# iostr735 register map
Registers are 16-bit, access not given, no defined reset value unless marked. A register's access mark holds for its fields unless they carry their own. Addresses are absolute; registers are grouped by the start of their names; [hi:lo] are bit positions; {n}, {i} and the like mark numbered series.

## TIM1
0xFFFFAC00 TIM1_ICAR
0xFFFFAC04 TIM1_ICBR
0xFFFFAC08 TIM1_OCAR
0xFFFFAC0C TIM1_OCBR
0xFFFFAC10 TIM1_CNTR
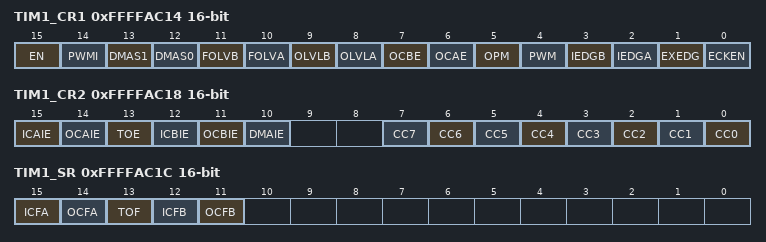
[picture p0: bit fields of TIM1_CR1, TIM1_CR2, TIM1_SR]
0xFFFFAC14 TIM1_CR1
  [15] EN, [14] PWMI, [13] DMAS1, [12] DMAS0, [11] FOLVB, [10] FOLVA, [9] OLVLB, [8] OLVLA, [7] OCBE, [6] OCAE, [5] OPM, [4] PWM, [3] IEDGB, [2] IEDGA, [1] EXEDG, [0] ECKEN
0xFFFFAC18 TIM1_CR2
  [15] ICAIE, [14] OCAIE, [13] TOE, [12] ICBIE, [11] OCBIE, [10] DMAIE, [n] CC{n} (n=0..7)
0xFFFFAC1C TIM1_SR
  [15] ICFA, [14] OCFA, [13] TOF, [12] ICFB, [11] OCFB

## TIM5
0xFFFFB000 TIM5_ICAR
0xFFFFB004 TIM5_ICBR
0xFFFFB008 TIM5_OCAR
0xFFFFB00C TIM5_OCBR
0xFFFFB010 TIM5_CNTR
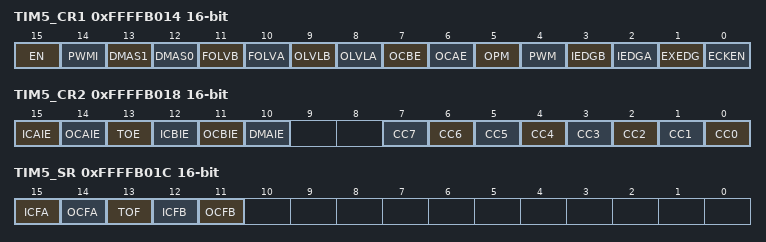
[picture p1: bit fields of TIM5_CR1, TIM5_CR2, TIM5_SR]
0xFFFFB014 TIM5_CR1
  [15] EN, [14] PWMI, [13] DMAS1, [12] DMAS0, [11] FOLVB, [10] FOLVA, [9] OLVLB, [8] OLVLA, [7] OCBE, [6] OCAE, [5] OPM, [4] PWM, [3] IEDGB, [2] IEDGA, [1] EXEDG, [0] ECKEN
0xFFFFB018 TIM5_CR2
  [15] ICAIE, [14] OCAIE, [13] TOE, [12] ICBIE, [11] OCBIE, [10] DMAIE, [n] CC{n} (n=0..7)
0xFFFFB01C TIM5_SR
  [15] ICFA, [14] OCFA, [13] TOF, [12] ICFB, [11] OCFB

## TIM6
0xFFFFB080 TIM6_ICAR
0xFFFFB084 TIM6_ICBR
0xFFFFB088 TIM6_OCAR
0xFFFFB08C TIM6_OCBR
0xFFFFB090 TIM6_CNTR
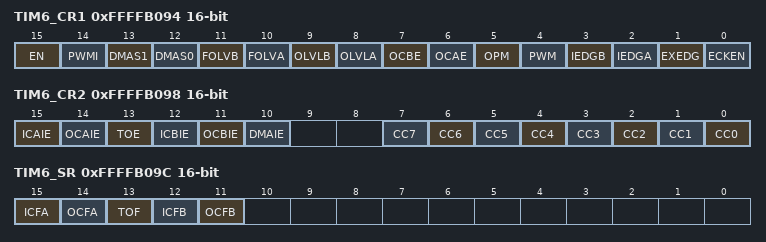
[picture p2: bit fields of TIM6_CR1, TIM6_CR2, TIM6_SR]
0xFFFFB094 TIM6_CR1
  [15] EN, [14] PWMI, [13] DMAS1, [12] DMAS0, [11] FOLVB, [10] FOLVA, [9] OLVLB, [8] OLVLA, [7] OCBE, [6] OCAE, [5] OPM, [4] PWM, [3] IEDGB, [2] IEDGA, [1] EXEDG, [0] ECKEN
0xFFFFB098 TIM6_CR2
  [15] ICAIE, [14] OCAIE, [13] TOE, [12] ICBIE, [11] OCBIE, [10] DMAIE, [n] CC{n} (n=0..7)
0xFFFFB09C TIM6_SR
  [15] ICFA, [14] OCFA, [13] TOF, [12] ICFB, [11] OCFB

## TIM7
0xFFFFB100 TIM7_ICAR
0xFFFFB104 TIM7_ICBR
0xFFFFB108 TIM7_OCAR
0xFFFFB10C TIM7_OCBR
0xFFFFB110 TIM7_CNTR
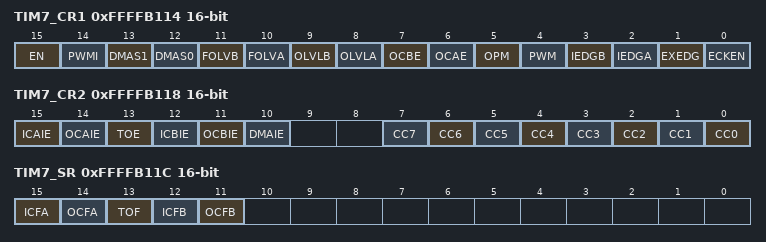
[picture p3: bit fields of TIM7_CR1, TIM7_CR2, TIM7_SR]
0xFFFFB114 TIM7_CR1
  [15] EN, [14] PWMI, [13] DMAS1, [12] DMAS0, [11] FOLVB, [10] FOLVA, [9] OLVLB, [8] OLVLA, [7] OCBE, [6] OCAE, [5] OPM, [4] PWM, [3] IEDGB, [2] IEDGA, [1] EXEDG, [0] ECKEN
0xFFFFB118 TIM7_CR2
  [15] ICAIE, [14] OCAIE, [13] TOE, [12] ICBIE, [11] OCBIE, [10] DMAIE, [n] CC{n} (n=0..7)
0xFFFFB11C TIM7_SR
  [15] ICFA, [14] OCFA, [13] TOF, [12] ICFB, [11] OCFB

## TIM8
0xFFFFB180 TIM8_ICAR
0xFFFFB184 TIM8_ICBR
0xFFFFB188 TIM8_OCAR
0xFFFFB18C TIM8_OCBR
0xFFFFB190 TIM8_CNTR
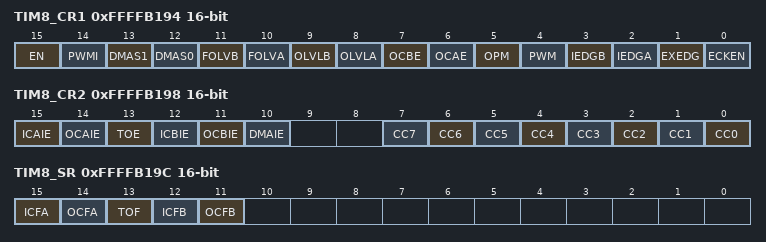
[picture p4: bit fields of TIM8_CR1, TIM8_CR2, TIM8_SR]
0xFFFFB194 TIM8_CR1
  [15] EN, [14] PWMI, [13] DMAS1, [12] DMAS0, [11] FOLVB, [10] FOLVA, [9] OLVLB, [8] OLVLA, [7] OCBE, [6] OCAE, [5] OPM, [4] PWM, [3] IEDGB, [2] IEDGA, [1] EXEDG, [0] ECKEN
0xFFFFB198 TIM8_CR2
  [15] ICAIE, [14] OCAIE, [13] TOE, [12] ICBIE, [11] OCBIE, [10] DMAIE, [n] CC{n} (n=0..7)
0xFFFFB19C TIM8_SR
  [15] ICFA, [14] OCFA, [13] TOF, [12] ICFB, [11] OCFB

## TIM9
0xFFFFB200 TIM9_ICAR
0xFFFFB204 TIM9_ICBR
0xFFFFB208 TIM9_OCAR
0xFFFFB20C TIM9_OCBR
0xFFFFB210 TIM9_CNTR
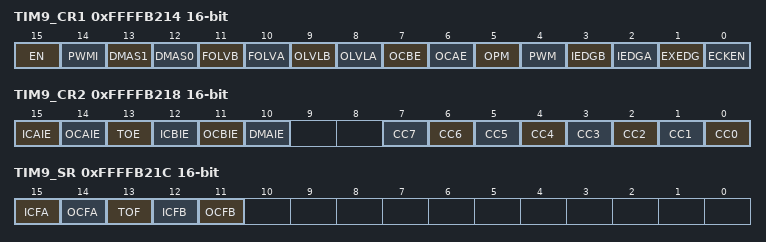
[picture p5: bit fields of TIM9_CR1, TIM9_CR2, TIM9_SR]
0xFFFFB214 TIM9_CR1
  [15] EN, [14] PWMI, [13] DMAS1, [12] DMAS0, [11] FOLVB, [10] FOLVA, [9] OLVLB, [8] OLVLA, [7] OCBE, [6] OCAE, [5] OPM, [4] PWM, [3] IEDGB, [2] IEDGA, [1] EXEDG, [0] ECKEN
0xFFFFB218 TIM9_CR2
  [15] ICAIE, [14] OCAIE, [13] TOE, [12] ICBIE, [11] OCBIE, [10] DMAIE, [n] CC{n} (n=0..7)
0xFFFFB21C TIM9_SR
  [15] ICFA, [14] OCFA, [13] TOF, [12] ICFB, [11] OCFB

## WIU
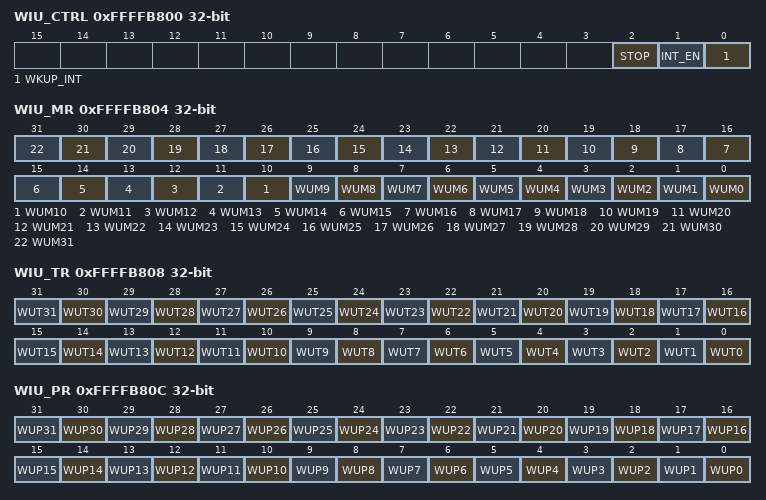
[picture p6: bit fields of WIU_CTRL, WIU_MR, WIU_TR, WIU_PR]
0xFFFFB800 WIU_CTRL 32-bit
  [2] STOP, [1] INT_EN, [0] WKUP_INT
0xFFFFB804 WIU_MR 32-bit
  [n] WUM{n} (n=0..31)
0xFFFFB808 WIU_TR 32-bit
  [n] WUT{n} (n=0..31)
0xFFFFB80C WIU_PR 32-bit
  [n] WUP{n} (n=0..31)
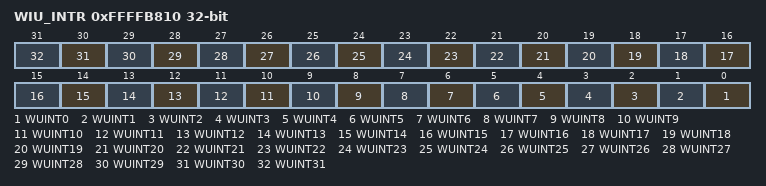
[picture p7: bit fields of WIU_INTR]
0xFFFFB810 WIU_INTR 32-bit
  [n] WUINT{n} (n=0..31)

## APB1
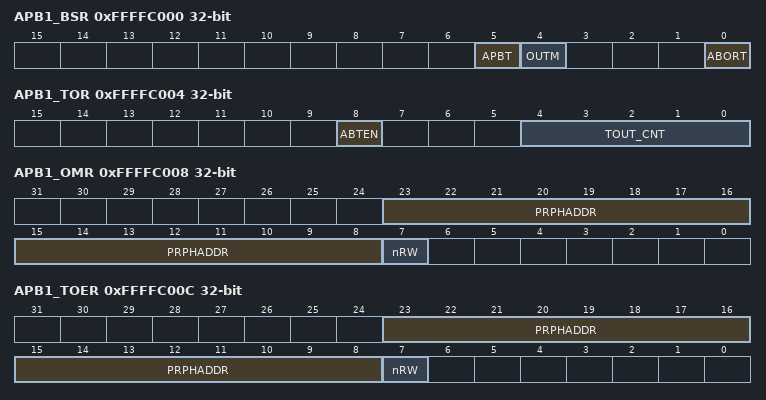
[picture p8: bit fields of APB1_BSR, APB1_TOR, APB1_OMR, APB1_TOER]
0xFFFFC000 APB1_BSR 32-bit
  [5] APBT, [4] OUTM, [0] ABORT
0xFFFFC004 APB1_TOR 32-bit
  [8] ABTEN, [4:0] TOUT_CNT
0xFFFFC008 APB1_OMR 32-bit
  [23:8] PRPHADDR, [7] nRW
0xFFFFC00C APB1_TOER 32-bit
  [23:8] PRPHADDR, [7] nRW
